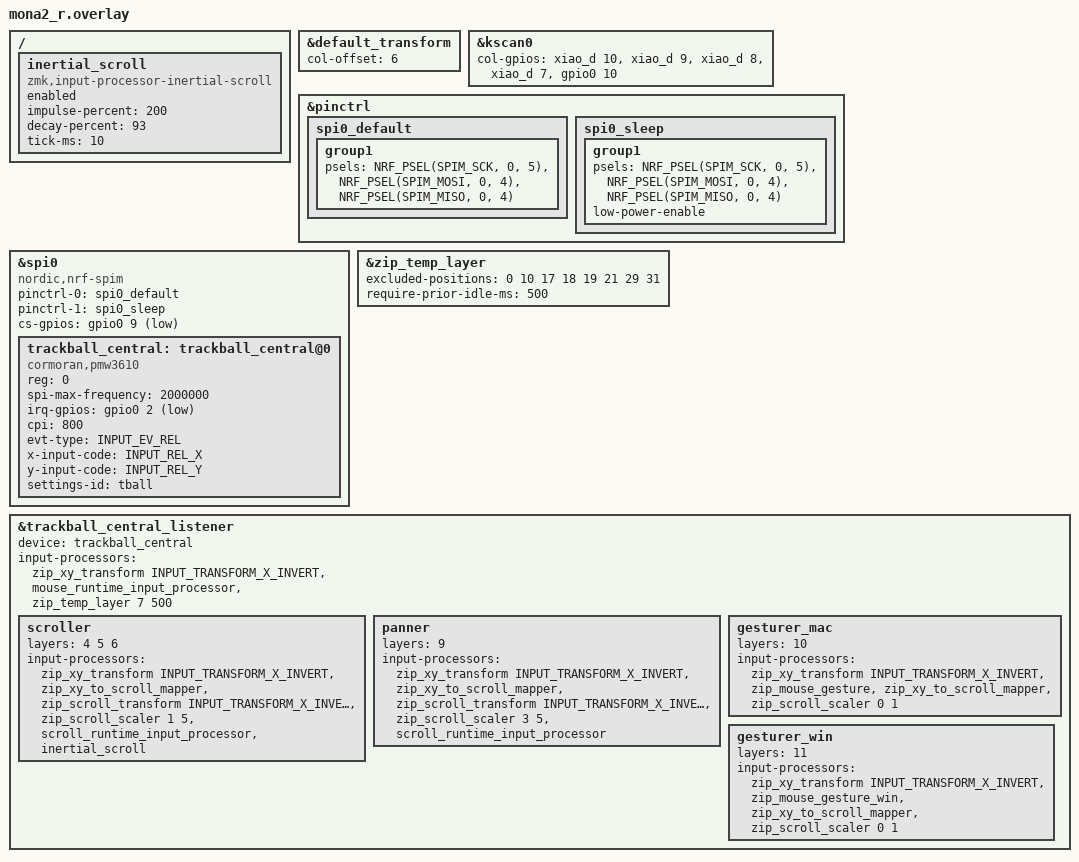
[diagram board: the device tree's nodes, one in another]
#include "mona2.dtsi"
#include <input/processors.dtsi>
#include <input/processors/runtime-input-processor.dtsi>
#include <zephyr/dt-bindings/input/input-event-codes.h>

// zip_mouse_gesture_win / mouse-gesture.dtsi は mona2.dtsi で定義・include 済み。

/ {
    // 慣性スクロール (shakushakupanda/zmk-module-mouse-gesture-rpc)
    // ZMK v0.4 移行に伴い、razilyis の PMW3610 ドライバフォークが持っていた
    // inertial-scroll-* プロパティ (ドライバ機能) から、入力プロセッサ方式へ移行した。
    // 有効範囲は inertial-scroll-layers ではなく「どのチェーンに挿すか」で決まるため、
    // 下の scroller (layers = <4 5 6>) の末尾にのみ挿してある。
    inertial_scroll: inertial_scroll {
        compatible = "zmk,input-processor-inertial-scroll";
        status = "okay";
        #input-processor-cells = <0>;
        enabled;                    // 既定で有効 (モジュール既定はオフ)
        impulse-percent = <200>;    // 旧 inertial-scroll-gain-pct = 200
        decay-percent = <93>;       // 旧 inertial-scroll-decay-pct = 93
        tick-ms = <10>;             // 旧 inertial-scroll-interval-ms = 10
        // min-velocity-q8 は旧 inertial-scroll-threshold (=10) と尺度が異なるため
        // 既定値 96 のまま様子を見る。余韻が長すぎる/短すぎる場合はここを増減する。
    };
};

&default_transform {
    col-offset = <6>;
};

&kscan0 {
    col-gpios
        = <&xiao_d 10 GPIO_ACTIVE_HIGH>
        , <&xiao_d 9 GPIO_ACTIVE_HIGH>
        , <&xiao_d 8 GPIO_ACTIVE_HIGH>
        , <&xiao_d 7 GPIO_ACTIVE_HIGH>
        , <&gpio0 10 GPIO_ACTIVE_HIGH>
        ;
};

&pinctrl {
    // SPI pin setup for right-side trackball
    spi0_default: spi0_default {
        group1 {
            psels = <NRF_PSEL(SPIM_SCK, 0, 5)>,
                <NRF_PSEL(SPIM_MOSI, 0, 4)>,
                <NRF_PSEL(SPIM_MISO, 0, 4)>;
        };
    };

    // Low-power pin state while sleeping
    spi0_sleep: spi0_sleep {
        group1 {
            psels = <NRF_PSEL(SPIM_SCK, 0, 5)>,
                <NRF_PSEL(SPIM_MOSI, 0, 4)>,
                <NRF_PSEL(SPIM_MISO, 0, 4)>;
            low-power-enable;
        };
    };
};

&spi0 {
    status = "okay";
    compatible = "nordic,nrf-spim";
    pinctrl-0 = <&spi0_default>;
    pinctrl-1 = <&spi0_sleep>;
    pinctrl-names = "default", "sleep";
    cs-gpios = <&gpio0 9 GPIO_ACTIVE_LOW>;

    trackball_central: trackball_central@0 {
        status = "okay";
        // ZMK v0.4 (Zephyr 4.1) が純正 "pixart,pmw3610" ドライバを取り込んだため、
        // 旧 compatible は衝突して使えない。cormoran 氏の custom Studio RPC 対応版
        // (compatible = "cormoran,pmw3610") へ移行した。
        // 慣性スクロールはこのドライバには無いので、入力プロセッサ &inertial_scroll
        // (このファイル冒頭で定義) が肩代わりする。
        compatible = "cormoran,pmw3610";
        reg = <0>;
        spi-max-frequency = <2000000>;
        irq-gpios = <&gpio0 2 (GPIO_ACTIVE_LOW | GPIO_PULL_UP)>;
        cpi = <800>;  // 600→800: センサー感度アップ。スクロール/ジェスチャー側は scaler・threshold・stroke-size で補正済み
        evt-type = <INPUT_EV_REL>;
        x-input-code = <INPUT_REL_X>;
        y-input-code = <INPUT_REL_Y>;
        // DYA Studio 上でこのセンサーを識別するための短い ID
        settings-id = "tball";
        // 軸の反転は CONFIG_PMW3610_SWAP_XY / _INVERT_X / _INVERT_Y (mona2_r.conf) で指定する。
        // ただし現行は入力チェーン側の zip_xy_transform で X 反転を効かせているため未設定。
        // COROPIT を使う場合は README の手順を参照。
    };
};

// 20260404
&zip_temp_layer {
    excluded-positions = <0 10 17 18 19 21 29 31>;
    require-prior-idle-ms = <500>;  // 300→500: タイピング中の振動でAMLが誤発火するのを抑制(打鍵後この時間はボールが動いてもMOUSE層へ移行しない)
};

// Runtime input listener for right-side trackball
&trackball_central_listener {
    status = "okay";
    device = <&trackball_central>;
    // オートマウスレイヤー(AML): ボール操作で MOUSE 層(=6) を一時有効化
    input-processors = <&zip_xy_transform INPUT_TRANSFORM_X_INVERT &mouse_runtime_input_processor &zip_temp_layer 7 500>;

    scroller {
        layers = <4 5 6>;   // NUM(4)/NAV_MAC(5)/NAV_WIN(6) でスクロール有効
        input-processors =
            <&zip_xy_transform INPUT_TRANSFORM_X_INVERT
             &zip_xy_to_scroll_mapper
             &zip_scroll_transform INPUT_TRANSFORM_X_INVERT
             &zip_scroll_scaler 1 5
             &scroll_runtime_input_processor
             &inertial_scroll>;   // scaler 1/4→1/5: cpi 600→800 の補正(体感速度ほぼ同等)
                                  // 慣性スクロールはこのチェーンにのみ挿す(=旧 inertial-scroll-layers <4 5 6> 相当)
    };

    // P長押し(layer 9): 2D自由スクロール(パン)。ざっと移動する用途なので scroller より高速
    panner {
        layers = <9>;
        input-processors =
            <&zip_xy_transform INPUT_TRANSFORM_X_INVERT
             &zip_xy_to_scroll_mapper
             &zip_scroll_transform INPUT_TRANSFORM_X_INVERT
             &zip_scroll_scaler 3 5
             &scroll_runtime_input_processor>;   // scaler 3/5: scroller(1/5)の3倍。広範囲をざっと移動する用途
    };

    // Q長押し(layer 10): Mac ウィンドウスナップ(Rectangle)
    // X_INVERT はデフォルトチェーンと同じ向き補正(無いと左右ストロークが反転する)
    // zip_xy_to_scroll_mapper + scaler 0/1: REL_X/Y を WHEEL に型変換し値を0にすることでカーソル移動を防ぐ
    // (PAN と同じ原理。suppress-movement の STOP と違い、排他チェーン内での型変換は確実にカーソルをロックする)
    gesturer_mac {
        layers = <10>;
        input-processors = <
            &zip_xy_transform INPUT_TRANSFORM_X_INVERT
            &zip_mouse_gesture
            &zip_xy_to_scroll_mapper
            &zip_scroll_scaler 0 1
        >;
    };

    // Q長押し(layer 11): Win ウィンドウスナップ(Win+矢印)
    gesturer_win {
        layers = <11>;
        input-processors = <
            &zip_xy_transform INPUT_TRANSFORM_X_INVERT
            &zip_mouse_gesture_win
            &zip_xy_to_scroll_mapper
            &zip_scroll_scaler 0 1
        >;
    };

};

